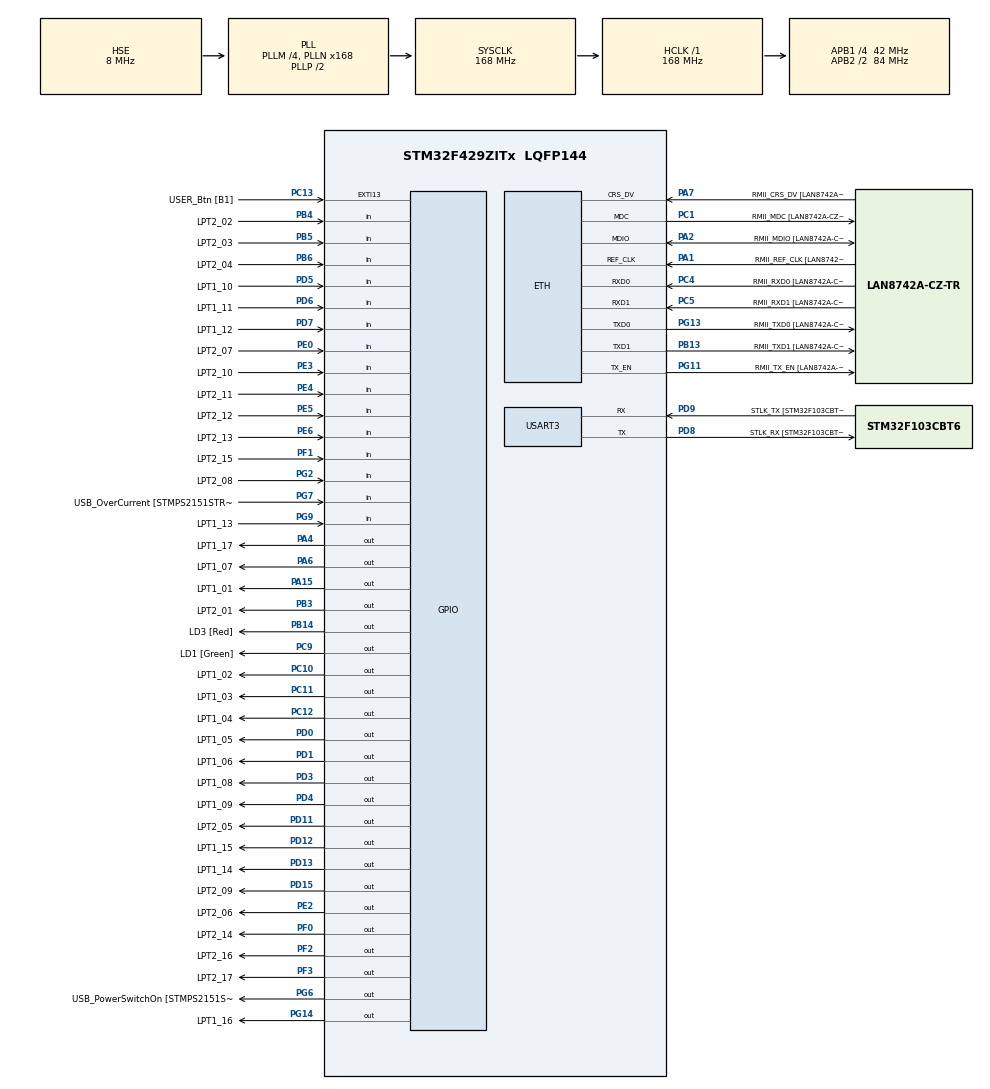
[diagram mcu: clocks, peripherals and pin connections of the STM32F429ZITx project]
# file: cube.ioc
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ETH.MediaInterface=ETH_MEDIA_INTERFACE_RMII
ETH.PHY_Name=LAN8742A_PHY_ADDRESS
ETH.PHY_Value=0
ETH.PhyAddress=0
FREERTOS.Tasks01=defaultTask,0,128,StartDefaultTask,Default,NULL
LWIP.GATEWAY_ADDRESS=169.254.001.001
LWIP.IP_ADDRESS=169.254.001.003
LWIP.LWIP_AUTOIP=0
LWIP.LWIP_DHCP=0
LWIP.LWIP_DHCP_AUTOIP_COOP=0
LWIP.LWIP_DHCP_AUTOIP_COOP_TRIES=4
LWIP.LWIP_HTTPD=0
LWIP.MEMP_NUM_PBUF=32
LWIP.MEMP_NUM_RAW_PCB=8
LWIP.MEMP_NUM_TCP_PCB=16
LWIP.MEMP_NUM_TCP_PCB_LISTEN=32
LWIP.MEMP_NUM_UDP_PCB=8
LWIP.MEM_SIZE=4096
LWIP.NETMASK_ADDRESS=255.255.255.000
LWIP.Version=v2.0.3_Cube
Mcu.Family=STM32F4
Mcu.Name=STM32F429ZITx
Mcu.Package=LQFP144
NVIC.ETH_IRQn=true\:5\:0\:false\:false\:true\:true\:false
NVIC.PriorityGroup=NVIC_PRIORITYGROUP_4
NVIC.TIM2_IRQn=true\:0\:0\:false\:false\:true\:false\:false
NVIC.TimeBase=TIM2_IRQn
NVIC.TimeBaseIP=TIM2
PA1.GPIO_Label=RMII_REF_CLK [LAN8742A-CZ-TR_REFCLK0]
PA1.Mode=RMII
PA1.Signal=ETH_REF_CLK
PA10.GPIO_Label=USB_ID
PA10.Signal=USB_OTG_FS_ID
PA11.GPIO_Label=USB_DM
PA11.Signal=USB_OTG_FS_DM
PA12.GPIO_Label=USB_DP
PA12.Signal=USB_OTG_FS_DP
PA13.GPIO_Label=TMS
PA13.Mode=Serial_Wire
PA13.Signal=SYS_JTMS-SWDIO
PA14.GPIO_Label=TCK
PA14.Mode=Serial_Wire
PA14.Signal=SYS_JTCK-SWCLK
PA15.GPIO_Label=LPT1_01
PA15.Signal=GPIO_Output
PA2.GPIO_Label=RMII_MDIO [LAN8742A-CZ-TR_MDIO]
PA2.Mode=RMII
PA2.Signal=ETH_MDIO
PA4.GPIO_Label=LPT1_17
PA4.Signal=GPIO_Output
PA6.GPIO_Label=LPT1_07
PA6.Signal=GPIO_Output
PA7.GPIO_Label=RMII_CRS_DV [LAN8742A-CZ-TR_CRS_DV]
PA7.Mode=RMII
PA7.Signal=ETH_CRS_DV
PA8.GPIO_Label=USB_SOF [TP1]
PA8.Signal=USB_OTG_FS_SOF
PA9.GPIO_Label=USB_VBUS
PA9.Signal=USB_OTG_FS_VBUS
PB13.GPIO_Label=RMII_TXD1 [LAN8742A-CZ-TR_TXD1]
PB13.Mode=RMII
PB13.Signal=ETH_TXD1
PB14.GPIO_Label=LD3 [Red]
PB14.Signal=GPIO_Output
PB3.GPIO_Label=LPT2_01
PB3.Signal=GPIO_Output
PB4.GPIO_Label=LPT2_02
PB4.GPIO_PuPd=GPIO_PULLDOWN
PB4.Signal=GPIO_Input
PB5.GPIO_Label=LPT2_03
PB5.GPIO_PuPd=GPIO_PULLDOWN
PB5.Signal=GPIO_Input
PB6.GPIO_Label=LPT2_04
PB6.GPIO_PuPd=GPIO_PULLDOWN
PB6.Signal=GPIO_Input
PC1.GPIO_Label=RMII_MDC [LAN8742A-CZ-TR_MDC]
PC1.Mode=RMII
PC1.Signal=ETH_MDC
PC10.GPIO_Label=LPT1_02
PC10.Signal=GPIO_Output
PC11.GPIO_Label=LPT1_03
PC11.Signal=GPIO_Output
PC12.GPIO_Label=LPT1_04
PC12.Signal=GPIO_Output
PC13.GPIO_Label=USER_Btn [B1]
PC13.Signal=GPXTI13
PC14/OSC32_IN.Mode=LSE-External-Oscillator
PC14/OSC32_IN.Signal=RCC_OSC32_IN
PC15/OSC32_OUT.Mode=LSE-External-Oscillator
PC15/OSC32_OUT.Signal=RCC_OSC32_OUT
PC4.GPIO_Label=RMII_RXD0 [LAN8742A-CZ-TR_RXD0]
PC4.Mode=RMII
PC4.Signal=ETH_RXD0
PC5.GPIO_Label=RMII_RXD1 [LAN8742A-CZ-TR_RXD1]
PC5.Mode=RMII
PC5.Signal=ETH_RXD1
PC9.GPIO_Label=LD1 [Green]
PC9.Signal=GPIO_Output
PD0.GPIO_Label=LPT1_05
PD0.Signal=GPIO_Output
PD1.GPIO_Label=LPT1_06
PD1.Signal=GPIO_Output
PD11.GPIO_Label=LPT2_05
PD11.Signal=GPIO_Output
PD12.GPIO_Label=LPT1_15
PD12.Signal=GPIO_Output
PD13.GPIO_Label=LPT1_14
PD13.Signal=GPIO_Output
PD15.GPIO_Label=LPT2_09
PD15.Signal=GPIO_Output
PD3.GPIO_Label=LPT1_08
PD3.Signal=GPIO_Output
PD4.GPIO_Label=LPT1_09
PD4.Signal=GPIO_Output
PD5.GPIO_Label=LPT1_10
PD5.GPIO_PuPd=GPIO_PULLDOWN
PD5.Signal=GPIO_Input
PD6.GPIO_Label=LPT1_11
PD6.GPIO_PuPd=GPIO_PULLDOWN
PD6.Signal=GPIO_Input
PD7.GPIO_Label=LPT1_12
PD7.GPIO_PuPd=GPIO_PULLDOWN
PD7.Signal=GPIO_Input
PD8.GPIO_Label=STLK_RX [STM32F103CBT6_PA3]
PD8.Mode=Asynchronous
PD8.Signal=USART3_TX
PD9.GPIO_Label=STLK_TX [STM32F103CBT6_PA2]
PD9.Mode=Asynchronous
PD9.Signal=USART3_RX
PE0.GPIO_Label=LPT2_07
PE0.GPIO_PuPd=GPIO_PULLDOWN
PE0.Signal=GPIO_Input
PE2.GPIO_Label=LPT2_06
PE2.Signal=GPIO_Output
PE3.GPIO_Label=LPT2_10
PE3.GPIO_PuPd=GPIO_PULLDOWN
PE3.Signal=GPIO_Input
PE4.GPIO_Label=LPT2_11
PE4.GPIO_PuPd=GPIO_PULLDOWN
PE4.Signal=GPIO_Input
PE5.GPIO_Label=LPT2_12
PE5.GPIO_PuPd=GPIO_PULLDOWN
PE5.Signal=GPIO_Input
PE6.GPIO_Label=LPT2_13
PE6.Signal=GPIO_Input
PF0.GPIO_Label=LPT2_14
PF0.Signal=GPIO_Output
PF1.GPIO_Label=LPT2_15
PF1.GPIO_PuPd=GPIO_PULLDOWN
PF1.Signal=GPIO_Input
PF2.GPIO_Label=LPT2_16
PF2.Signal=GPIO_Output
PF3.GPIO_Label=LPT2_17
PF3.Signal=GPIO_Output
PG11.GPIO_Label=RMII_TX_EN [LAN8742A-CZ-TR_TXEN]
PG11.Mode=RMII
PG11.Signal=ETH_TX_EN
PG13.GPIO_Label=RMII_TXD0 [LAN8742A-CZ-TR_TXD0]
PG13.Mode=RMII
PG13.Signal=ETH_TXD0
PG14.GPIO_Label=LPT1_16
PG14.Signal=GPIO_Output
PG2.GPIO_Label=LPT2_08
PG2.Signal=GPIO_Input
PG6.GPIO_Label=USB_PowerSwitchOn [STMPS2151STR_EN]
PG6.Signal=GPIO_Output
PG7.GPIO_Label=USB_OverCurrent [STMPS2151STR_FAULT]
PG7.Signal=GPIO_Input
PG9.GPIO_Label=LPT1_13
PG9.GPIO_PuPd=GPIO_PULLDOWN
PG9.Signal=GPIO_Input
PH0/OSC_IN.GPIO_Label=MCO [STM32F103CBT6_PA8]
PH0/OSC_IN.Mode=HSE-External-Clock-Source
PH0/OSC_IN.Signal=RCC_OSC_IN
PH1/OSC_OUT.Mode=HSE-External-Clock-Source
PH1/OSC_OUT.Signal=RCC_OSC_OUT
ProjectManager.HeapSize=0x200
ProjectManager.StackSize=0x400
ProjectManager.TargetToolchain=TrueSTUDIO
RCC.48MHZClocksFreq_Value=48000000
RCC.AHBFreq_Value=168000000
RCC.APB1CLKDivider=RCC_HCLK_DIV4
RCC.APB1Freq_Value=42000000
RCC.APB1TimFreq_Value=84000000
RCC.APB2CLKDivider=RCC_HCLK_DIV2
RCC.APB2Freq_Value=84000000
RCC.APB2TimCLKDivider=2
RCC.APB2TimFreq_Value=168000000
RCC.CortexFreq_Value=168000000
RCC.HCLKFreq_Value=168000000
RCC.HSE_VALUE=8000000
RCC.HSI_VALUE=16000000
RCC.PLLM=4
RCC.PLLMUL=RCC_PLL_MUL9
RCC.PLLN=168
RCC.PLLQ=7
RCC.PLLSourceVirtual=RCC_PLLSOURCE_HSE
RCC.PRESCALERUSB=RCC_USBCLKSOURCE_PLL_DIV1_5
RCC.SYSCLKFreq_VALUE=168000000
RCC.SYSCLKSource=RCC_SYSCLKSOURCE_PLLCLK
RCC.SYSCLKSourceVirtual=RCC_SYSCLKSOURCE_PLLCLK
RCC.USBFreq_Value=48000000
RCC.VCOOutputFreq_Value=336000000
USART3.VirtualMode=VM_ASYNC
VP_FREERTOS_VS_ENABLE.Mode=Enabled
VP_LWIP_VS_Enabled.Mode=Enabled
VP_SYS_VS_tim2.Mode=TIM2
board=NUCLEO-F429ZI

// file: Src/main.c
/* USER CODE BEGIN Header */
/**
  ******************************************************************************
  * @file           : main.c
  * @brief          : Main program body
  ******************************************************************************
  * This notice applies to any and all portions of this file
  * that are not between comment pairs USER CODE BEGIN and
  * USER CODE END. Other portions of this file, whether
  * inserted by the user or by software development tools
  * are owned by their respective copyright owners.
  *
  * Copyright (c) 2019 STMicroelectronics International N.V.
  * All rights reserved.
  *
  * Redistribution and use in source and binary forms, with or without
  * modification, are permitted, provided that the following conditions are met:
  *
  * 1. Redistribution of source code must retain the above copyright notice,
  *    this list of conditions and the following disclaimer.
  * 2. Redistributions in binary form must reproduce the above copyright notice,
  *    this list of conditions and the following disclaimer in the documentation
  *    and/or other materials provided with the distribution.
  * 3. Neither the name of STMicroelectronics nor the names of other
  *    contributors to this software may be used to endorse or promote products
  *    derived from this software without specific written permission.
  * 4. This software, including modifications and/or derivative works of this
  *    software, must execute solely and exclusively on microcontroller or
  *    microprocessor devices manufactured by or for STMicroelectronics.
  * 5. Redistribution and use of this software other than as permitted under
  *    this license is void and will automatically terminate your rights under
  *    this license.
  *
  * THIS SOFTWARE IS PROVIDED BY STMICROELECTRONICS AND CONTRIBUTORS "AS IS"
  * AND ANY EXPRESS, IMPLIED OR STATUTORY WARRANTIES, INCLUDING, BUT NOT
  * LIMITED TO, THE IMPLIED WARRANTIES OF MERCHANTABILITY, FITNESS FOR A
  * PARTICULAR PURPOSE AND NON-INFRINGEMENT OF THIRD PARTY INTELLECTUAL PROPERTY
  * RIGHTS ARE DISCLAIMED TO THE FULLEST EXTENT PERMITTED BY LAW. IN NO EVENT
  * SHALL STMICROELECTRONICS OR CONTRIBUTORS BE LIABLE FOR ANY DIRECT, INDIRECT,
  * INCIDENTAL, SPECIAL, EXEMPLARY, OR CONSEQUENTIAL DAMAGES (INCLUDING, BUT NOT
  * LIMITED TO, PROCUREMENT OF SUBSTITUTE GOODS OR SERVICES; LOSS OF USE, DATA,
  * OR PROFITS; OR BUSINESS INTERRUPTION) HOWEVER CAUSED AND ON ANY THEORY OF
  * LIABILITY, WHETHER IN CONTRACT, STRICT LIABILITY, OR TORT (INCLUDING
  * NEGLIGENCE OR OTHERWISE) ARISING IN ANY WAY OUT OF THE USE OF THIS SOFTWARE,
  * EVEN IF ADVISED OF THE POSSIBILITY OF SUCH DAMAGE.
  *
  ******************************************************************************
  */
/* USER CODE END Header */

#include "main.h"
#include "cmsis_os.h"
#include "lwip.h"

UART_HandleTypeDef huart3;

osThreadId defaultTaskHandle;

void SystemClock_Config(void);
static void MX_GPIO_Init(void);
static void MX_USART3_UART_Init(void);
void StartDefaultTask(void const * argument);

int main(void)
{

  /* MCU Configuration--------------------------------------------------------*/

  /* Reset of all peripherals, Initializes the Flash interface and the Systick. */
  HAL_Init();

  /* Configure the system clock */
  SystemClock_Config();

  /* Initialize all configured peripherals */
  MX_GPIO_Init();
  MX_USART3_UART_Init();
  /* USER CODE BEGIN 2 */

  extern void init_main(void);
  init_main();

  /* USER CODE END 2 */

  /* Create the thread(s) */
  /* definition and creation of defaultTask */
  osThreadDef(defaultTask, StartDefaultTask, osPriorityNormal, 0, 128);
  defaultTaskHandle = osThreadCreate(osThread(defaultTask), NULL);

  /* Start scheduler */
  osKernelStart();

  /* We should never get here as control is now taken by the scheduler */

  /* Infinite loop */
  while (1)
  {

  }
}

void SystemClock_Config(void)
{
  RCC_OscInitTypeDef RCC_OscInitStruct = {0};
  RCC_ClkInitTypeDef RCC_ClkInitStruct = {0};

  /**Configure the main internal regulator output voltage
  */
  __HAL_RCC_PWR_CLK_ENABLE();
  __HAL_PWR_VOLTAGESCALING_CONFIG(PWR_REGULATOR_VOLTAGE_SCALE1);
  /**Initializes the CPU, AHB and APB busses clocks
  */
  RCC_OscInitStruct.OscillatorType = RCC_OSCILLATORTYPE_HSE;
  RCC_OscInitStruct.HSEState = RCC_HSE_BYPASS;
  RCC_OscInitStruct.PLL.PLLState = RCC_PLL_ON;
  RCC_OscInitStruct.PLL.PLLSource = RCC_PLLSOURCE_HSE;
  RCC_OscInitStruct.PLL.PLLM = 4;
  RCC_OscInitStruct.PLL.PLLN = 168;
  RCC_OscInitStruct.PLL.PLLP = RCC_PLLP_DIV2;
  RCC_OscInitStruct.PLL.PLLQ = 7;
  if (HAL_RCC_OscConfig(&RCC_OscInitStruct) != HAL_OK)
  {
    Error_Handler();
  }
  /**Initializes the CPU, AHB and APB busses clocks
  */
  RCC_ClkInitStruct.ClockType = RCC_CLOCKTYPE_HCLK|RCC_CLOCKTYPE_SYSCLK
                              |RCC_CLOCKTYPE_PCLK1|RCC_CLOCKTYPE_PCLK2;
  RCC_ClkInitStruct.SYSCLKSource = RCC_SYSCLKSOURCE_PLLCLK;
  RCC_ClkInitStruct.AHBCLKDivider = RCC_SYSCLK_DIV1;
  RCC_ClkInitStruct.APB1CLKDivider = RCC_HCLK_DIV4;
  RCC_ClkInitStruct.APB2CLKDivider = RCC_HCLK_DIV2;

  if (HAL_RCC_ClockConfig(&RCC_ClkInitStruct, FLASH_LATENCY_5) != HAL_OK)
  {
    Error_Handler();
  }
}

static void MX_USART3_UART_Init(void)
{

  huart3.Instance = USART3;
  huart3.Init.BaudRate = 115200;
  huart3.Init.WordLength = UART_WORDLENGTH_8B;
  huart3.Init.StopBits = UART_STOPBITS_1;
  huart3.Init.Parity = UART_PARITY_NONE;
  huart3.Init.Mode = UART_MODE_TX_RX;
  huart3.Init.HwFlowCtl = UART_HWCONTROL_NONE;
  huart3.Init.OverSampling = UART_OVERSAMPLING_16;
  if (HAL_UART_Init(&huart3) != HAL_OK)
  {
    Error_Handler();
  }

}

static void MX_GPIO_Init(void)
{
  GPIO_InitTypeDef GPIO_InitStruct = {0};

  /* GPIO Ports Clock Enable */
  __HAL_RCC_GPIOE_CLK_ENABLE();
  __HAL_RCC_GPIOC_CLK_ENABLE();
  __HAL_RCC_GPIOF_CLK_ENABLE();
  __HAL_RCC_GPIOH_CLK_ENABLE();
  __HAL_RCC_GPIOA_CLK_ENABLE();
  __HAL_RCC_GPIOB_CLK_ENABLE();
  __HAL_RCC_GPIOD_CLK_ENABLE();
  __HAL_RCC_GPIOG_CLK_ENABLE();

  /*Configure GPIO pin Output Level */
  HAL_GPIO_WritePin(LPT2_06_GPIO_Port, LPT2_06_Pin, GPIO_PIN_RESET);

  /*Configure GPIO pin Output Level */
  HAL_GPIO_WritePin(GPIOF, LPT2_14_Pin|LPT2_16_Pin|LPT2_17_Pin, GPIO_PIN_RESET);

  /*Configure GPIO pin Output Level */
  HAL_GPIO_WritePin(GPIOA, LPT1_17_Pin|LPT1_01_Pin, GPIO_PIN_RESET);

  /*Configure GPIO pin Output Level */
  HAL_GPIO_WritePin(GPIOB, LD3_Pin|LPT2_01_Pin, GPIO_PIN_RESET);

  /*Configure GPIO pin Output Level */
  HAL_GPIO_WritePin(GPIOD, LPT2_05_Pin|LPT1_15_Pin|LPT1_14_Pin|LPT2_09_Pin
                          |LPT1_05_Pin|LPT1_06_Pin|LPT1_07_Pin|LPT1_08_Pin
                          |LPT1_09_Pin, GPIO_PIN_RESET);

  /*Configure GPIO pin Output Level */
  HAL_GPIO_WritePin(GPIOG, USB_PowerSwitchOn_Pin|LPT1_16_Pin, GPIO_PIN_RESET);

  /*Configure GPIO pin Output Level */
  HAL_GPIO_WritePin(GPIOC, LD1_Pin|LPT1_02_Pin|LPT1_03_Pin|LPT1_04_Pin, GPIO_PIN_RESET);

  /*Configure GPIO pin : LPT2_06_Pin */
  GPIO_InitStruct.Pin = LPT2_06_Pin;
  GPIO_InitStruct.Mode = GPIO_MODE_OUTPUT_PP;
  GPIO_InitStruct.Pull = GPIO_NOPULL;
  GPIO_InitStruct.Speed = GPIO_SPEED_FREQ_LOW;
  HAL_GPIO_Init(LPT2_06_GPIO_Port, &GPIO_InitStruct);

  /*Configure GPIO pins : LPT2_10_Pin LPT2_11_Pin LPT2_12_Pin LPT2_07_Pin */
  GPIO_InitStruct.Pin = LPT2_10_Pin|LPT2_11_Pin|LPT2_12_Pin|LPT2_07_Pin;
  GPIO_InitStruct.Mode = GPIO_MODE_INPUT;
  GPIO_InitStruct.Pull = GPIO_PULLDOWN;
  HAL_GPIO_Init(GPIOE, &GPIO_InitStruct);

  /*Configure GPIO pin : LPT2_13_Pin */
  GPIO_InitStruct.Pin = LPT2_13_Pin;
  GPIO_InitStruct.Mode = GPIO_MODE_INPUT;
  GPIO_InitStruct.Pull = GPIO_NOPULL;
  HAL_GPIO_Init(LPT2_13_GPIO_Port, &GPIO_InitStruct);

  /*Configure GPIO pin : USER_Btn_Pin */
  GPIO_InitStruct.Pin = USER_Btn_Pin;
  GPIO_InitStruct.Mode = GPIO_MODE_IT_RISING;
  GPIO_InitStruct.Pull = GPIO_NOPULL;
  HAL_GPIO_Init(USER_Btn_GPIO_Port, &GPIO_InitStruct);

  /*Configure GPIO pins : LPT2_14_Pin LPT2_16_Pin LPT2_17_Pin */
  GPIO_InitStruct.Pin = LPT2_14_Pin|LPT2_16_Pin|LPT2_17_Pin;
  GPIO_InitStruct.Mode = GPIO_MODE_OUTPUT_PP;
  GPIO_InitStruct.Pull = GPIO_NOPULL;
  GPIO_InitStruct.Speed = GPIO_SPEED_FREQ_LOW;
  HAL_GPIO_Init(GPIOF, &GPIO_InitStruct);

  /*Configure GPIO pin : LPT2_15_Pin */
  GPIO_InitStruct.Pin = LPT2_15_Pin;
  GPIO_InitStruct.Mode = GPIO_MODE_INPUT;
  GPIO_InitStruct.Pull = GPIO_PULLDOWN;
  HAL_GPIO_Init(LPT2_15_GPIO_Port, &GPIO_InitStruct);

  /*Configure GPIO pins : LPT1_17_Pin LPT1_01_Pin */
  GPIO_InitStruct.Pin = LPT1_17_Pin|LPT1_01_Pin;
  GPIO_InitStruct.Mode = GPIO_MODE_OUTPUT_PP;
  GPIO_InitStruct.Pull = GPIO_NOPULL;
  GPIO_InitStruct.Speed = GPIO_SPEED_FREQ_LOW;
  HAL_GPIO_Init(GPIOA, &GPIO_InitStruct);

  /*Configure GPIO pins : LD3_Pin LPT2_01_Pin */
  GPIO_InitStruct.Pin = LD3_Pin|LPT2_01_Pin;
  GPIO_InitStruct.Mode = GPIO_MODE_OUTPUT_PP;
  GPIO_InitStruct.Pull = GPIO_NOPULL;
  GPIO_InitStruct.Speed = GPIO_SPEED_FREQ_LOW;
  HAL_GPIO_Init(GPIOB, &GPIO_InitStruct);

  /*Configure GPIO pins : LPT2_05_Pin LPT1_15_Pin LPT1_14_Pin LPT2_09_Pin
                           LPT1_05_Pin LPT1_06_Pin LPT1_07_Pin LPT1_08_Pin
                           LPT1_09_Pin */
  GPIO_InitStruct.Pin = LPT2_05_Pin|LPT1_15_Pin|LPT1_14_Pin|LPT2_09_Pin
                          |LPT1_05_Pin|LPT1_06_Pin|LPT1_07_Pin|LPT1_08_Pin
                          |LPT1_09_Pin;
  GPIO_InitStruct.Mode = GPIO_MODE_OUTPUT_PP;
  GPIO_InitStruct.Pull = GPIO_NOPULL;
  GPIO_InitStruct.Speed = GPIO_SPEED_FREQ_LOW;
  HAL_GPIO_Init(GPIOD, &GPIO_InitStruct);

  /*Configure GPIO pins : LPT2_08_Pin USB_OverCurrent_Pin */
  GPIO_InitStruct.Pin = LPT2_08_Pin|USB_OverCurrent_Pin;
  GPIO_InitStruct.Mode = GPIO_MODE_INPUT;
  GPIO_InitStruct.Pull = GPIO_NOPULL;
  HAL_GPIO_Init(GPIOG, &GPIO_InitStruct);

  /*Configure GPIO pins : USB_PowerSwitchOn_Pin LPT1_16_Pin */
  GPIO_InitStruct.Pin = USB_PowerSwitchOn_Pin|LPT1_16_Pin;
  GPIO_InitStruct.Mode = GPIO_MODE_OUTPUT_PP;
  GPIO_InitStruct.Pull = GPIO_NOPULL;
  GPIO_InitStruct.Speed = GPIO_SPEED_FREQ_LOW;
  HAL_GPIO_Init(GPIOG, &GPIO_InitStruct);

  /*Configure GPIO pins : LD1_Pin LPT1_02_Pin LPT1_03_Pin LPT1_04_Pin */
  GPIO_InitStruct.Pin = LD1_Pin|LPT1_02_Pin|LPT1_03_Pin|LPT1_04_Pin;
  GPIO_InitStruct.Mode = GPIO_MODE_OUTPUT_PP;
  GPIO_InitStruct.Pull = GPIO_NOPULL;
  GPIO_InitStruct.Speed = GPIO_SPEED_FREQ_LOW;
  HAL_GPIO_Init(GPIOC, &GPIO_InitStruct);

  /*Configure GPIO pins : USB_SOF_Pin USB_ID_Pin USB_DM_Pin USB_DP_Pin */
  GPIO_InitStruct.Pin = USB_SOF_Pin|USB_ID_Pin|USB_DM_Pin|USB_DP_Pin;
  GPIO_InitStruct.Mode = GPIO_MODE_AF_PP;
  GPIO_InitStruct.Pull = GPIO_NOPULL;
  GPIO_InitStruct.Speed = GPIO_SPEED_FREQ_VERY_HIGH;
  GPIO_InitStruct.Alternate = GPIO_AF10_OTG_FS;
  HAL_GPIO_Init(GPIOA, &GPIO_InitStruct);

  /*Configure GPIO pin : USB_VBUS_Pin */
  GPIO_InitStruct.Pin = USB_VBUS_Pin;
  GPIO_InitStruct.Mode = GPIO_MODE_INPUT;
  GPIO_InitStruct.Pull = GPIO_NOPULL;
  HAL_GPIO_Init(USB_VBUS_GPIO_Port, &GPIO_InitStruct);

  /*Configure GPIO pins : LPT1_10_Pin LPT1_11_Pin LPT1_12_Pin */
  GPIO_InitStruct.Pin = LPT1_10_Pin|LPT1_11_Pin|LPT1_12_Pin;
  GPIO_InitStruct.Mode = GPIO_MODE_INPUT;
  GPIO_InitStruct.Pull = GPIO_PULLDOWN;
  HAL_GPIO_Init(GPIOD, &GPIO_InitStruct);

  /*Configure GPIO pin : LPT1_13_Pin */
  GPIO_InitStruct.Pin = LPT1_13_Pin;
  GPIO_InitStruct.Mode = GPIO_MODE_INPUT;
  GPIO_InitStruct.Pull = GPIO_PULLDOWN;
  HAL_GPIO_Init(LPT1_13_GPIO_Port, &GPIO_InitStruct);

  /*Configure GPIO pins : LPT2_02_Pin LPT2_03_Pin LPT2_04_Pin */
  GPIO_InitStruct.Pin = LPT2_02_Pin|LPT2_03_Pin|LPT2_04_Pin;
  GPIO_InitStruct.Mode = GPIO_MODE_INPUT;
  GPIO_InitStruct.Pull = GPIO_PULLDOWN;
  HAL_GPIO_Init(GPIOB, &GPIO_InitStruct);

}

/* USER CODE BEGIN 4 */
extern void init_net(void);
/* USER CODE END 4 */

void StartDefaultTask(void const * argument)
{
  /* init code for LWIP */
  MX_LWIP_Init();

  /* USER CODE BEGIN 5 */
  init_net();
  /* Infinite loop */
  for(;;)
  {
    osDelay(1);
  }
  /* USER CODE END 5 */
}

void HAL_TIM_PeriodElapsedCallback(TIM_HandleTypeDef *htim)
{
  if (htim->Instance == TIM2) {
    HAL_IncTick();
  }
}

void Error_Handler(void)
{
}

/************************ (C) COPYRIGHT STMicroelectronics *****END OF FILE****/
